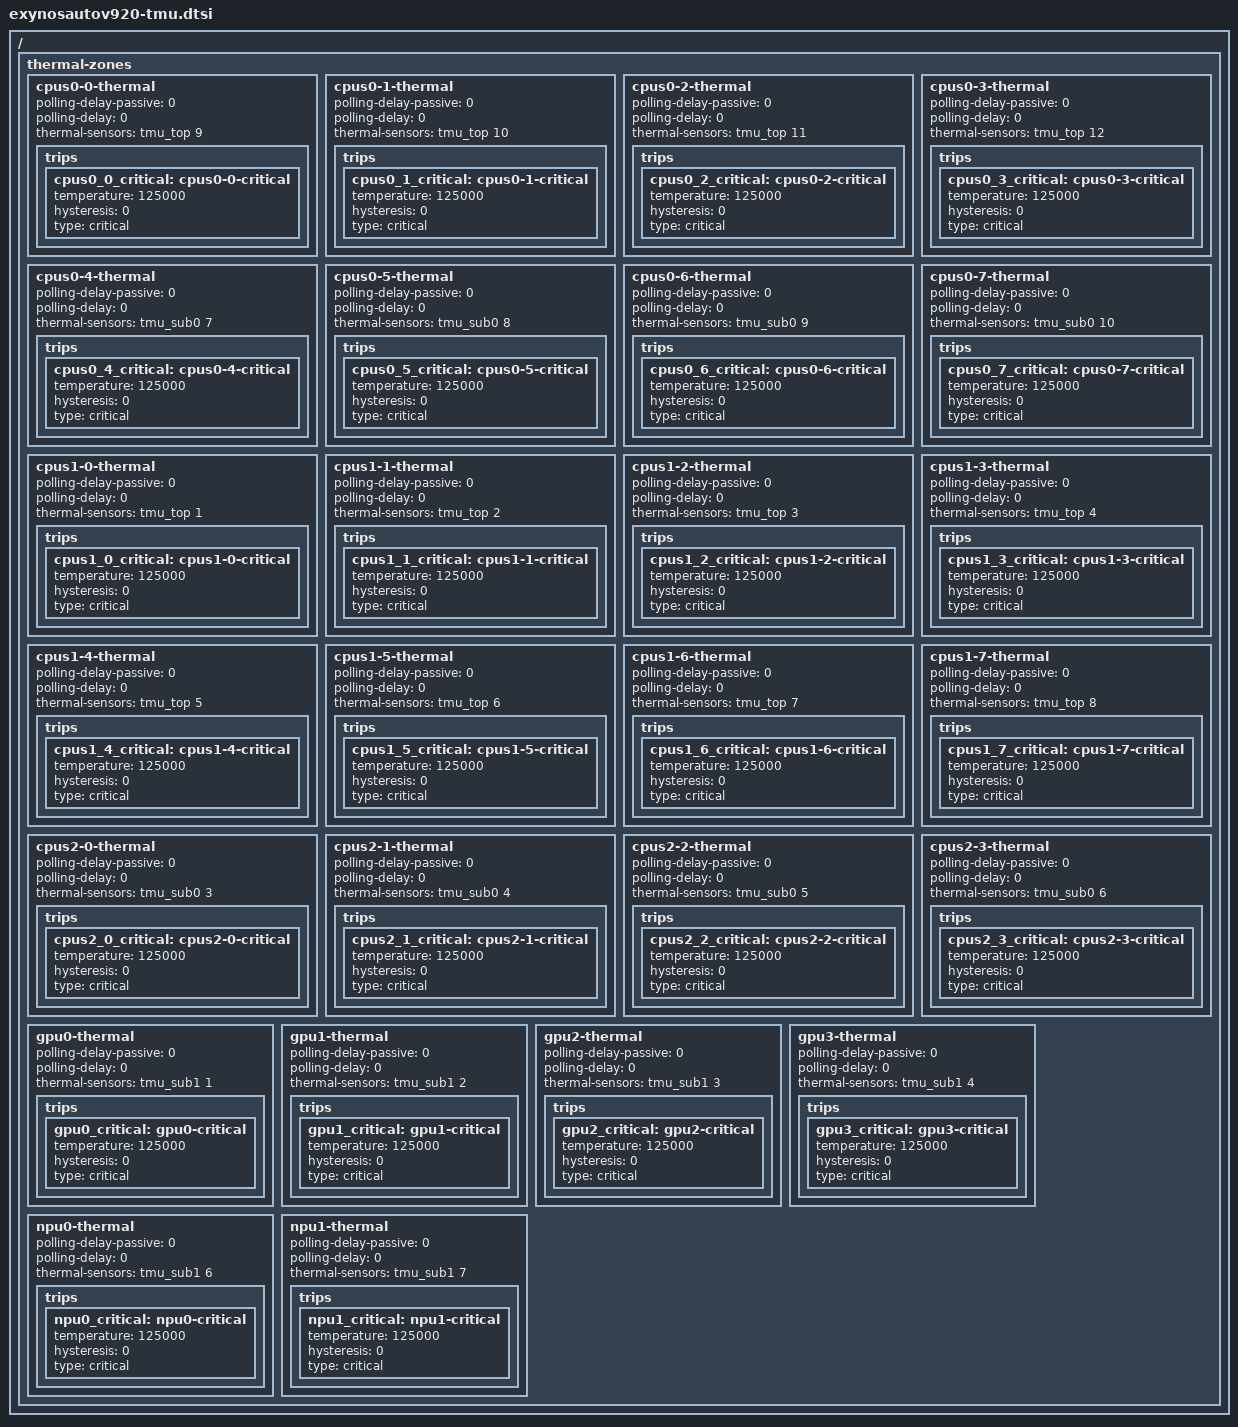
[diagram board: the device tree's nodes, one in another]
// SPDX-License-Identifier: GPL-2.0
/*
 * Samsung's ExynosAuto920 TMU configurations device tree source
 *
 * Copyright (c) 2020 Samsung Electronics Co., Ltd.
 *
 * Samsung's ExynosAuto920 SoC TMU(Thermal Managemenut Unit) are listed as
 * device tree nodes in this file.
 */

/ {
	thermal-zones {
		cpus0-0-thermal {
			polling-delay-passive = <0>;
			polling-delay = <0>;
			thermal-sensors = <&tmu_top 9>;

			trips {
				cpus0_0_critical: cpus0-0-critical {
					temperature = <125000>;	/* millicelsius */
					hysteresis = <0>;	/* millicelsius */
					type = "critical";
				};
			};
		};

		cpus0-1-thermal {
			polling-delay-passive = <0>;
			polling-delay = <0>;
			thermal-sensors = <&tmu_top 10>;

			trips {
				cpus0_1_critical: cpus0-1-critical {
					temperature = <125000>;	/* millicelsius */
					hysteresis = <0>;	/* millicelsius */
					type = "critical";
				};
			};
		};

		cpus0-2-thermal {
			polling-delay-passive = <0>;
			polling-delay = <0>;
			thermal-sensors = <&tmu_top 11>;

			trips {
				cpus0_2_critical: cpus0-2-critical {
					temperature = <125000>;	/* millicelsius */
					hysteresis = <0>;	/* millicelsius */
					type = "critical";
				};
			};
		};

		cpus0-3-thermal {
			polling-delay-passive = <0>;
			polling-delay = <0>;
			thermal-sensors = <&tmu_top 12>;

			trips {
				cpus0_3_critical: cpus0-3-critical {
					temperature = <125000>;	/* millicelsius */
					hysteresis = <0>;	/* millicelsius */
					type = "critical";
				};
			};
		};

		cpus0-4-thermal {
			polling-delay-passive = <0>;
			polling-delay = <0>;
			thermal-sensors = <&tmu_sub0 7>;

			trips {
				cpus0_4_critical: cpus0-4-critical {
					temperature = <125000>;	/* millicelsius */
					hysteresis = <0>;	/* millicelsius */
					type = "critical";
				};
			};
		};

		cpus0-5-thermal {
			polling-delay-passive = <0>;
			polling-delay = <0>;
			thermal-sensors = <&tmu_sub0 8>;

			trips {
				cpus0_5_critical: cpus0-5-critical {
					temperature = <125000>;	/* millicelsius */
					hysteresis = <0>;	/* millicelsius */
					type = "critical";
				};
			};
		};

		cpus0-6-thermal {
			polling-delay-passive = <0>;
			polling-delay = <0>;
			thermal-sensors = <&tmu_sub0 9>;

			trips {
				cpus0_6_critical: cpus0-6-critical {
					temperature = <125000>;	/* millicelsius */
					hysteresis = <0>;	/* millicelsius */
					type = "critical";
				};
			};
		};

		cpus0-7-thermal {
			polling-delay-passive = <0>;
			polling-delay = <0>;
			thermal-sensors = <&tmu_sub0 10>;

			trips {
				cpus0_7_critical: cpus0-7-critical {
					temperature = <125000>;	/* millicelsius */
					hysteresis = <0>;	/* millicelsius */
					type = "critical";
				};
			};
		};

		cpus1-0-thermal {
			polling-delay-passive = <0>;
			polling-delay = <0>;
			thermal-sensors = <&tmu_top 1>;

			trips {
				cpus1_0_critical: cpus1-0-critical {
					temperature = <125000>;	/* millicelsius */
					hysteresis = <0>;	/* millicelsius */
					type = "critical";
				};
			};
		};

		cpus1-1-thermal {
			polling-delay-passive = <0>;
			polling-delay = <0>;
			thermal-sensors = <&tmu_top 2>;

			trips {
				cpus1_1_critical: cpus1-1-critical {
					temperature = <125000>;	/* millicelsius */
					hysteresis = <0>;	/* millicelsius */
					type = "critical";
				};
			};
		};

		cpus1-2-thermal {
			polling-delay-passive = <0>;
			polling-delay = <0>;
			thermal-sensors = <&tmu_top 3>;

			trips {
				cpus1_2_critical: cpus1-2-critical {
					temperature = <125000>;	/* millicelsius */
					hysteresis = <0>;	/* millicelsius */
					type = "critical";
				};
			};
		};

		cpus1-3-thermal {
			polling-delay-passive = <0>;
			polling-delay = <0>;
			thermal-sensors = <&tmu_top 4>;

			trips {
				cpus1_3_critical: cpus1-3-critical {
					temperature = <125000>;	/* millicelsius */
					hysteresis = <0>;	/* millicelsius */
					type = "critical";
				};
			};
		};

		cpus1-4-thermal {
			polling-delay-passive = <0>;
			polling-delay = <0>;
			thermal-sensors = <&tmu_top 5>;

			trips {
				cpus1_4_critical: cpus1-4-critical {
					temperature = <125000>;	/* millicelsius */
					hysteresis = <0>;	/* millicelsius */
					type = "critical";
				};
			};
		};

		cpus1-5-thermal {
			polling-delay-passive = <0>;
			polling-delay = <0>;
			thermal-sensors = <&tmu_top 6>;

			trips {
				cpus1_5_critical: cpus1-5-critical {
					temperature = <125000>;	/* millicelsius */
					hysteresis = <0>;	/* millicelsius */
					type = "critical";
				};
			};
		};

		cpus1-6-thermal {
			polling-delay-passive = <0>;
			polling-delay = <0>;
			thermal-sensors = <&tmu_top 7>;

			trips {
				cpus1_6_critical: cpus1-6-critical {
					temperature = <125000>;	/* millicelsius */
					hysteresis = <0>;	/* millicelsius */
					type = "critical";
				};
			};
		};

		cpus1-7-thermal {
			polling-delay-passive = <0>;
			polling-delay = <0>;
			thermal-sensors = <&tmu_top 8>;

			trips {
				cpus1_7_critical: cpus1-7-critical {
					temperature = <125000>;	/* millicelsius */
					hysteresis = <0>;	/* millicelsius */
					type = "critical";
				};
			};
		};

		cpus2-0-thermal {
			polling-delay-passive = <0>;
			polling-delay = <0>;
			thermal-sensors = <&tmu_sub0 3>;

			trips {
				cpus2_0_critical: cpus2-0-critical {
					temperature = <125000>;	/* millicelsius */
					hysteresis = <0>;	/* millicelsius */
					type = "critical";
				};
			};
		};

		cpus2-1-thermal {
			polling-delay-passive = <0>;
			polling-delay = <0>;
			thermal-sensors = <&tmu_sub0 4>;

			trips {
				cpus2_1_critical: cpus2-1-critical {
					temperature = <125000>;	/* millicelsius */
					hysteresis = <0>;	/* millicelsius */
					type = "critical";
				};
			};
		};

		cpus2-2-thermal {
			polling-delay-passive = <0>;
			polling-delay = <0>;
			thermal-sensors = <&tmu_sub0 5>;

			trips {
				cpus2_2_critical: cpus2-2-critical {
					temperature = <125000>;	/* millicelsius */
					hysteresis = <0>;	/* millicelsius */
					type = "critical";
				};
			};
		};

		cpus2-3-thermal {
			polling-delay-passive = <0>;
			polling-delay = <0>;
			thermal-sensors = <&tmu_sub0 6>;

			trips {
				cpus2_3_critical: cpus2-3-critical {
					temperature = <125000>;	/* millicelsius */
					hysteresis = <0>;	/* millicelsius */
					type = "critical";
				};
			};
		};

		gpu0-thermal {
			polling-delay-passive = <0>;
			polling-delay = <0>;
			thermal-sensors = <&tmu_sub1 1>;

			trips {
				gpu0_critical: gpu0-critical {
					temperature = <125000>;	/* millicelsius */
					hysteresis = <0>;	/* millicelsius */
					type = "critical";
				};
			};
		};

		gpu1-thermal {
			polling-delay-passive = <0>;
			polling-delay = <0>;
			thermal-sensors = <&tmu_sub1 2>;

			trips {
				gpu1_critical: gpu1-critical {
					temperature = <125000>;	/* millicelsius */
					hysteresis = <0>;	/* millicelsius */
					type = "critical";
				};
			};
		};

		gpu2-thermal {
			polling-delay-passive = <0>;
			polling-delay = <0>;
			thermal-sensors = <&tmu_sub1 3>;

			trips {
				gpu2_critical: gpu2-critical {
					temperature = <125000>;	/* millicelsius */
					hysteresis = <0>;	/* millicelsius */
					type = "critical";
				};
			};
		};

		gpu3-thermal {
			polling-delay-passive = <0>;
			polling-delay = <0>;
			thermal-sensors = <&tmu_sub1 4>;

			trips {
				gpu3_critical: gpu3-critical {
					temperature = <125000>;	/* millicelsius */
					hysteresis = <0>;	/* millicelsius */
					type = "critical";
				};
			};
		};

		npu0-thermal {
			polling-delay-passive = <0>;
			polling-delay = <0>;
			thermal-sensors = <&tmu_sub1 6>;

			trips {
				npu0_critical: npu0-critical {
					temperature = <125000>;	/* millicelsius */
					hysteresis = <0>;	/* millicelsius */
					type = "critical";
				};
			};
		};

		npu1-thermal {
			polling-delay-passive = <0>;
			polling-delay = <0>;
			thermal-sensors = <&tmu_sub1 7>;

			trips {
				npu1_critical: npu1-critical {
					temperature = <125000>;	/* millicelsius */
					hysteresis = <0>;	/* millicelsius */
					type = "critical";
				};
			};
		};
	};
};
